# SF32LB56x register map
File version: 1.0
CPU: CM33 r0p1, little endian, MPU, FPU, 3 interrupt priority bits
Registers are 32-bit, read-write, reset 0x0 unless marked. A register's access mark holds for its fields unless they carry their own. Offsets are from the block's base; [hi:lo] are bit positions.

## USART1
Base 0x40004000
Same registers: USART2 0x40005000, USART3 0x40029000, USART4 0x50005000, USART5 0x50006000, USART6 0x50007000
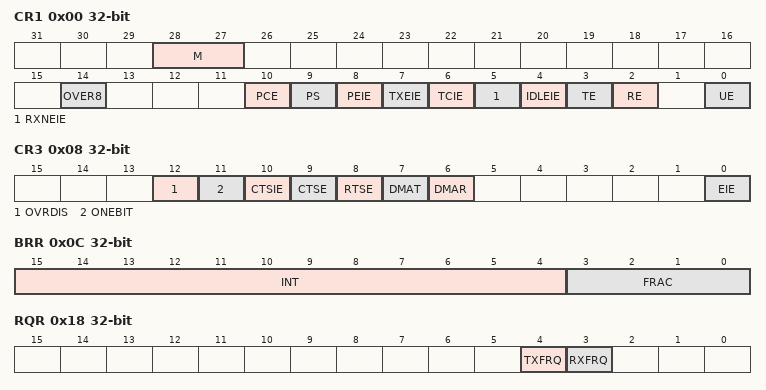
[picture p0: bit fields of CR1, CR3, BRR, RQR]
0x00 CR1 — Control Register 1
  [28:27] M — Mode bit indicates the length of the packet, including data bits and parity. Stop bits not included. 0: 6 bits (e.g. 6 data bits + no parity bit) 1: 7 bits (e.g. 6 data bits + 1 parity bit) 2: 8 bits (e.g. 7 data bits + 1 parity bit, or 6 data bits + 2 parity bits) 3: 9 bits (e.g. 8 data bits + 1 parity bit, or 7 data bits + 2 parity bits)
  [14] OVER8 — Oversampling mode 0: Oversampling by 16 1: Oversampling by 8
  [10] PCE — Parity check enable. If enabled, parity bit is inserted at the MSB position 0: parity check disabled 1: parity check enabled
  [9] PS — Parity select 0: even parity 1: odd parity
  [8] PEIE — Parity error interrupt enable 0: interrupt disabled 1: interrupt is generated whenever PE=1 in the ISR register
  [7] TXEIE — Tx empty interrupt enable 0: interrupt disabled 1: interrupt is generated whenver TXE=1 in the ISR register
  [6] TCIE — Transfer compelete interrupt enable 0: interrupt disabled 1: interrupt is generated whenever TC=1 in the ISR register
  [5] RXNEIE — Rx not empty interrupt enable 0: interrupt disabled 1: interrupt is generated whenever RXNE=1 in the ISR register
  [4] IDLEIE — Idle line interrupt enable 0: interrupt disabled 1: interrupt is generated whenever IDLE=1 in the ISR register
  [3] TE — Transmitter enable 0: transmitter is disabled 1: transmitter is enabled
  [2] RE — Receiver enable 0: receiver is disabled 1: receiver is enabled
  [0] UE — USART enable 0: disabled 1: enabled
0x04 CR2 — Control Register 2
  [13:12] STOP — Stop bits 0/1: 1 stop bit 2/3: 2 stop bits
0x08 CR3 — Control Register 3
  [12] OVRDIS — Overrun disable 0: overrun error flag (ORE) will be set if new data received but previous data not read. New data will not overwrite the content in RDR register. 1: overrun disabled. If new data is received before previous data is read, the new data will overwrite the content in RDR register and ORE flag remains unset.
  [11] ONEBIT — One bit sampling mode 0: 3-bit sampling mode, the sampling value is determined by the voted result out of 3 bits 1: 1-bit sampling mode
  [10] CTSIE — CTS interrupt enable 0: interrupt disabled 1: interrupt is generated whenever CTSIF=1 in the ISR register
  [9] CTSE — CTS enable 0: CTS hardware flow control disabled 1: CTS hardware flow control enabled, data is transmitted only when CTS input is asserted low
  [8] RTSE — RTS enable 0: RTS hardware flow control disabled 1: RTS hardware flow control enabled, RTS output is asserted low when new data can be received
  [7] DMAT — Transmitter DMA enable 0: DMA mode disabled for transmission 1: DMA mode enabled for transmission
  [6] DMAR — Receiver DMA enable 0: DMA mode disabled for reception 1: DMA mode enabled for reception
  [0] EIE — Error interrupt enable 0: interrupt disabled 1: interrupt is generated whenever FE=1 or ORE=1 or NF=1 in the ISR register
0x0C BRR — Baud Rate Register
  [15:4] INT — Integer part of baud rate prescaler If OVER8 = 0, Baud Rate = 48000000 / (INT + FRAC/16) / 16 If OVER8 = 1, Baud Rate = 48000000 / (INT + FRAC/16) / 8 For example: OVER=0, INT=3, FRAC=0, Baud Rate = 48000000/(3+0)/16 = 1Mbps OVER=0, INT=3, FRAC=4, Baud Rate = 48000000/(3+4/16)/16 = 923077 = 921600 + 1.6‰ OVER=1, INT=52, FRAC=1, Baud Rate = 48000000/(52+1/16)/8 = 115246 = 115200 + 0.4‰
  [3:0] FRAC — Fractional part of baud rate prescaler
0x18 RQR — Request Register
  [4] TXFRQ — Tx data flush requestReserved-Do not modify
  [3] RXFRQ — Rx data flush request. Write 1 to clear the RXNE flag and discard the current data in RDR
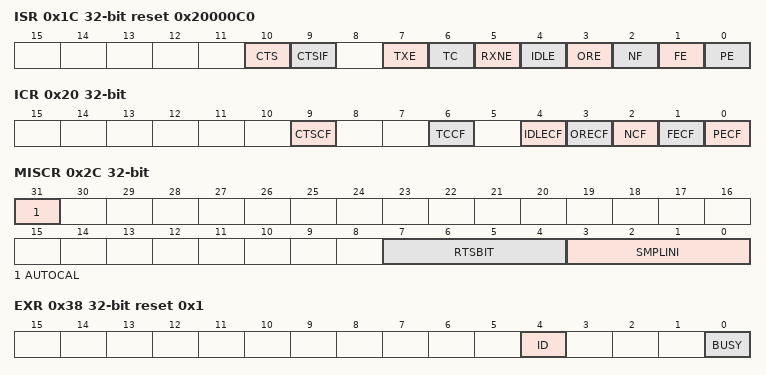
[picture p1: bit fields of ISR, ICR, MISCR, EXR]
0x1C ISR reset 0x20000C0 — Interrupt and Status Register
  [10] CTS — CTS input. Read this bit to get the raw status of the CTS line.
  [9] CTSIF — CTS interrupt flag. This bit is set by hardware whenever CTS input toggles. 0: no change on the CTS line 1: there is a change on the CTS line
  [7] TXE — Tx data empty 0: data is ready in TDR 1: data is already transferred to shift register, i.e. transmission is in progress or complete
  [6] TC — transmission complete. This bit is set by hardware if the transmission is complete 0: transmission is not complete 1: transmission is complete
  [5] RXNE — Rx data not empty. This bit is set by hardware when the received data is transferred into RDR register. 0: data is not received 1: data is ready in RDR to be read
  [4] IDLE — Idle line detected 0: no idle line is detected 1: idle line is detected
  [3] ORE — Overrun error. When new data is received but Rx buffer is not empty (i.e. previous data is not read yet), ORE is asserted and current RDR content is not lost. This feature can be disabled by set CR3_OVRDIS to 1. 0: no overrun error 1: overrun error is detected
  [2] NF — Noise flag. Noise means the samping values in the 3-bit sampling mode are not the same. 0: no noise is detected 1: noise is detected
  [1] FE — Framing error. This bit is set by hardware when stop bit is not correctly received 0: no framing error is detected 1: framing error is detected
  [0] PE — Parity error. This bit is set when a parity error is detected in the received packet. 0: no parity error 1: parity error detected
0x20 ICR — Interrupt flag Clear Register
  [9] CTSCF — CTS clear flag. Writing 1 to this bit clears the CTSIF flag in the ISR register.
  [6] TCCF — Transmission complete clear flag. Writing 1 to this bit clears the TC flag in the ISR register.
  [4] IDLECF — Idle line detected clear flag. Writing 1 to this bit clears the IDLECF flag in the ISR register.
  [3] ORECF — Overrun error clear flag. Writing 1 to this bit clears the ORE flag in the ISR register.
  [2] NCF — Noise detected clear flag. Writing 1 to this bit clears the NF flag in the ISR register.
  [1] FECF — Framing error clear flag. Writing 1 to this bit clears the FE flag in the ISR register.
  [0] PECF — Parity error clear flag. Wriring 1 to this bit clears the PE flag in the ISR register.
0x24 RDR — Receive Data Register
  [8:0] RDR — Received data
0x28 TDR — Transmit Data Register
  [8:0] TDR — Transmit data
0x2C MISCR — Miscellaneous Register
  [31] AUTOCAL
  [7:4] RTSBIT — assert RTS ahead of the frame completion (in number of bits)Reserved-Do not modify
  [3:0] SMPLINI — initial sample count, count down from this value to zero to reach the middle of the start bit in RxReserved-Do not modify
0x30 DRDR — Debug Receive Data Register
  [31:0] DATA — DbgUART is still a preliminary version in this project.
0x34 DTDR — Debug Receive Data Register
  [31:0] DATA
0x38 EXR reset 0x1 — Mutual Exclusive Register
  [4] ID, [0] BUSY
